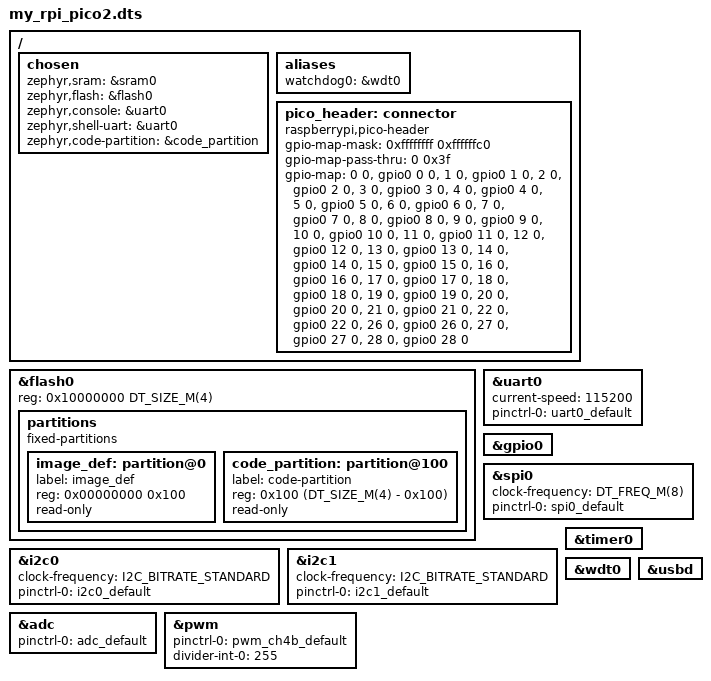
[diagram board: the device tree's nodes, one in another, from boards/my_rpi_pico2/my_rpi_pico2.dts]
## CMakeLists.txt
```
cmake_minimum_required(VERSION 3.20.0)

list(APPEND BOARD_ROOT ${CMAKE_CURRENT_SOURCE_DIR})
find_package(Zephyr REQUIRED HINTS $ENV{ZEPHYR_BASE})
project(my_zephyr_app)

target_sources(app PRIVATE src/main.cpp)
zephyr_syscall_include_directories(drivers/my_pico2driver/include)
add_subdirectory(drivers/my_pico2driver)
```

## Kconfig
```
menuconfig LED_SUBSYSTEM
    bool "LED Subsytem"
    default y

if LED_SUBSYSTEM

choice
    prompt "LED blink sleep time"
    default BLINK_SPEED_1000MS

config BLINK_SPEED_250MS
    bool "250ms (quick)"

config BLINK_SPEED_500MS
    bool "500ms (fast)"

config BLINK_SPEED_1000MS
    bool "1s (medium)"

config BLINK_SPEED_2000MS
    bool "2s (slow)"

endchoice

config BLINK_SLEEP_TIME_MS
    int # no prompt
    default 250 if BLINK_SPEED_250MS 
    default 500 if BLINK_SPEED_500MS 
    default 1000 if BLINK_SPEED_1000MS 
    default 2000 if BLINK_SPEED_2000MS 
    default 0

menuconfig ADV_LED_SETTINGS
    bool "Advanced LED settings"
    
if ADV_LED_SETTINGS

config LED_BRIGHTNESS
    int "LED brightness (0-100)"
    range 0 100
    default 100

config LED_FADE_DURATION_MS
    int "LED fade duration (ms)"
    range 0 5000
    default 500
  
endif # ADV_LED_SETTINGS

menu "Expert settings"
    visible if ADV_LED_SETTINGS

config ENABLE_LED_DEBUGGING
    bool "Enable LED debugging"

config CUSTOM_BLINK_PATTERN
    bool "Custom blink pattern"

endmenu

config APP_HEARTBEAT_PERIOD_MS
    int "App led blink period" 
    range 100 2000
    default 500

endif # LED_SUBSYSTEM

source "Kconfig.zephyr"
rsource "drivers/my_pico2driver/Kconfig"
```

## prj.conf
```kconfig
CONFIG_GPIO=y
CONFIG_LOG=y
CONFIG_MY_PICO2DRIVER=y
CONFIG_APPLICATION_DEFINED_SYSCALL=y

CONFIG_SERIAL=y
CONFIG_CONSOLE=y
CONFIG_UART_CONSOLE=y
CONFIG_STDOUT_CONSOLE=y
CONFIG_UART_LINE_CTRL=y

CONFIG_USB_DEVICE_STACK_NEXT=y
CONFIG_USB_CDC_ACM=y
CONFIG_CDC_ACM_SERIAL_INITIALIZE_AT_BOOT=y
CONFIG_CDC_ACM_SERIAL_PID=0x0004
CONFIG_CDC_ACM_SERIAL_PRODUCT_STRING="pico2 USBD console"

CONFIG_SHELL=y
CONFIG_MY_PICO2DRIVER_SHELL=y
```

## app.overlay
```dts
/ {
    aliases {
        app-led = &led0;
    };

    chosen {
        zephyr,console = &cdc_acm_uart0;
        zephyr,shell-uart = &cdc_acm_uart0;
    };

    my_pico2driver0: my_pico2driver {
        compatible = "my,pico2driver";
        status = "okay";
    };
};

&zephyr_udc0 {
    cdc_acm_uart0: cdc_acm_uart0 {
        compatible = "zephyr,cdc-acm-uart";
    };
};
```

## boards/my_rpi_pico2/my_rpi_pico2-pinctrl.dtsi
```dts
/*
 * Copyright (c) 2024, Andrew Featherstone
 * SPDX-License-Identifier: Apache-2.0
 */

#include <zephyr/dt-bindings/pinctrl/rpi-pico-rp2350a-pinctrl.h>

#include "my_rpi_pico-pinctrl-common.dtsi"
```

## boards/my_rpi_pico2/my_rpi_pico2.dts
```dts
/*
 * Copyright (c) 2024 Andrew Featherstone
 *
 * SPDX-License-Identifier: Apache-2.0
 */

#include <freq.h>

#include <zephyr/dt-bindings/i2c/i2c.h>
#include <zephyr/dt-bindings/pwm/pwm.h>

#include "my_rpi_pico2-pinctrl.dtsi"
#include "my_rpi_pico-led.dtsi"

/ {
	chosen {
		zephyr,sram = &sram0;
		zephyr,flash = &flash0;
		zephyr,console = &uart0;
		zephyr,shell-uart = &uart0;
		zephyr,code-partition = &code_partition;
	};

	aliases {
		watchdog0 = &wdt0;
	};

	pico_header: connector {
		compatible = "raspberrypi,pico-header";
		#gpio-cells = <2>;
		gpio-map-mask = <0xffffffff 0xffffffc0>;
		gpio-map-pass-thru = <0 0x3f>;
		gpio-map = <0 0 &gpio0 0 0>,	/* GP0 */
			<1 0 &gpio0 1 0>,	/* GP1 */
			<2 0 &gpio0 2 0>,	/* GP2 */
			<3 0 &gpio0 3 0>,	/* GP3 */
			<4 0 &gpio0 4 0>,	/* GP4 */
			<5 0 &gpio0 5 0>,	/* GP5 */
			<6 0 &gpio0 6 0>,	/* GP6 */
			<7 0 &gpio0 7 0>,	/* GP7 */
			<8 0 &gpio0 8 0>,	/* GP8 */
			<9 0 &gpio0 9 0>,	/* GP9 */
			<10 0 &gpio0 10 0>,	/* GP10 */
			<11 0 &gpio0 11 0>,	/* GP11 */
			<12 0 &gpio0 12 0>,	/* GP12 */
			<13 0 &gpio0 13 0>,	/* GP13 */
			<14 0 &gpio0 14 0>,	/* GP14 */
			<15 0 &gpio0 15 0>,	/* GP15 */
			<16 0 &gpio0 16 0>,	/* GP16 */
			<17 0 &gpio0 17 0>,	/* GP17 */
			<18 0 &gpio0 18 0>,	/* GP18 */
			<19 0 &gpio0 19 0>,	/* GP19 */
			<20 0 &gpio0 20 0>,	/* GP20 */
			<21 0 &gpio0 21 0>,	/* GP21 */
			<22 0 &gpio0 22 0>,	/* GP22 */
			<26 0 &gpio0 26 0>,	/* GP26 */
			<27 0 &gpio0 27 0>,	/* GP27 */
			<28 0 &gpio0 28 0>;	/* GP28 */
	};
};

&flash0 {
	reg = <0x10000000 DT_SIZE_M(4)>;

	partitions {
		compatible = "fixed-partitions";
		#address-cells = <1>;
		#size-cells = <1>;

		/* Reserved memory for an image definition block. The block is much
		 * smaller than 256 bytes, but in practice the linker places the vector
		 * table at a much larger alignment offset.
		 */
		image_def: partition@0 {
			label = "image_def";
			reg = <0x00000000 0x100>;
			read-only;
		};

		/*
		 * Usable flash. Starts at 0x100, after the image definition block.
		 * The partition size is 4MB minus the 0x100 bytes taken by the
		 * image definition.
		 */
		code_partition: partition@100 {
			label = "code-partition";
			reg = <0x100 (DT_SIZE_M(4) - 0x100)>;
			read-only;
		};
	};
};

&uart0 {
	current-speed = <115200>;
	status = "okay";
	pinctrl-0 = <&uart0_default>;
	pinctrl-names = "default";
};

gpio0_lo: &gpio0 {
	status = "okay";
};

&spi0 {
	clock-frequency = <DT_FREQ_M(8)>;
	pinctrl-0 = <&spi0_default>;
	pinctrl-names = "default";
};

&i2c0 {
	clock-frequency = <I2C_BITRATE_STANDARD>;
	pinctrl-0 = <&i2c0_default>;
	pinctrl-names = "default";
	status = "okay";
};

&i2c1 {
	clock-frequency = <I2C_BITRATE_STANDARD>;
	pinctrl-0 = <&i2c1_default>;
	pinctrl-names = "default";
	status = "okay";
};

&adc {
	pinctrl-0 = <&adc_default>;
	pinctrl-names = "default";
	status = "okay";
};

&pwm {
	pinctrl-0 = <&pwm_ch4b_default>;
	pinctrl-names = "default";
	divider-int-0 = <255>;
};

&timer0 {
	status = "okay";
};

&wdt0 {
	status = "okay";
};

zephyr_udc0: &usbd {
	status = "okay";
};

pico_serial: &uart0 {};
```

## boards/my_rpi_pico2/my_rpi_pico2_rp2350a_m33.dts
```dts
/*
 * Copyright (c) 2024 Andrew Featherstone
 *
 * SPDX-License-Identifier: Apache-2.0
 */

/dts-v1/;

/* The build system assumes that there's a cpucluster-specific file.
 *
 * This file provides composition of the device tree:
 * 1. The common features of the SoC
 * 2. Core-specific configuration.
 * 3. Board-specific configuration.
 */
#include <raspberrypi/rpi_pico/rp2350a.dtsi>
#include <raspberrypi/rpi_pico/m33.dtsi>

/* there's nothing specific to the Cortex-M33 cores vs the (not yet
 * implemented) Hazard3 cores.
 */
#include "my_rpi_pico2.dtsi"
```

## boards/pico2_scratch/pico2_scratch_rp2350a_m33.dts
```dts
/dts-v1/;

/* The build system assumes that there's a cpucluster-specific file.
 *
 * This file provides composition of the device tree:
 * 1. The common features of the SoC
 * 2. Core-specific configuration.
 * 3. Board-specific configuration.
 */
#include <raspberrypi/rpi_pico/rp2350a.dtsi>
#include <raspberrypi/rpi_pico/m33.dtsi>

#include <zephyr/dt-bindings/pinctrl/rpi-pico-rp2350a-pinctrl.h>

/ {
    model = "Pico2 from Sratch";
    compatible = "myrasberrypi,pico2_scratch";

	chosen {
		zephyr,sram = &sram0;
		zephyr,flash = &flash0;
		zephyr,console = &uart0;
		zephyr,shell-uart = &uart0;
		zephyr,code-partition = &code_partition;
	};

    leds {
        compatible = "gpio-leds";
        led0: led_0 {
            gpios = <&gpio0 25 GPIO_ACTIVE_HIGH>;
            label = "LED";
        };
    };

    aliases {
		led0 = &led0;
    };
};

&pinctrl {
    uart0_default: uart0_default {
        group1 {
            pinmux = <UART0_TX_P0>;
        };  
        group2 {
            pinmux = <UART0_RX_P1>;
            input-enable;
        };  
    }; 
};

&flash0 {
	reg = <0x10000000 DT_SIZE_M(4)>;

	partitions {
		compatible = "fixed-partitions";
		#address-cells = <1>;
		#size-cells = <1>;

		/* Reserved memory for an image definition block. The block is much
		 * smaller than 256 bytes, but in practice the linker places the vector
		 * table at a much larger alignment offset.
		 */
		image_def: partition@0 {
			label = "image_def";
			reg = <0x00000000 0x100>;
			read-only;
		};

		/*
		 * Usable flash. Starts at 0x100, after the image definition block.
		 * The partition size is 4MB minus the 0x100 bytes taken by the
		 * image definition.
		 */
		code_partition: partition@100 {
			label = "code-partition";
			reg = <0x100 (DT_SIZE_M(4) - 0x100)>;
			read-only;
		};
	};
};

&uart0 {
	current-speed = <115200>;
	status = "okay";
	pinctrl-0 = <&uart0_default>;
	pinctrl-names = "default";
};

gpio0_lo: &gpio0 {
	status = "okay";
};

pico_serial: &uart0 {};
```

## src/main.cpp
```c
#include <zephyr/drivers/gpio.h>
#include <zephyr/drivers/sensor.h>
#include <zephyr/drivers/uart.h>
#include <zephyr/usb/usb_device.h>

#include <zephyr/kernel.h>
#include <zephyr/logging/log.h>
#include <zephyr/sys/printk.h>

#include <mypico2.h>

#define LED_DEFAULT_BLINK_TIME 3000

/* Use the USB CDC ACM - Lack for serial cable */
BUILD_ASSERT(DT_NODE_HAS_COMPAT(DT_CHOSEN(zephyr_console), zephyr_cdc_acm_uart), "Console device is not ACM CDC UART device");

LOG_MODULE_REGISTER(main, LOG_LEVEL_INF);

int main(void)
{
    bool led_state = false;
    struct sensor_value sval;
    const struct device* sensor_dev = DEVICE_DT_GET(DT_NODELABEL(my_pico2driver0));
    int ret = -1;

    const struct device *usb_dev = DEVICE_DT_GET(DT_CHOSEN(zephyr_console));
    uint32_t dtr = 0;

    /* Poll if the DTR flag was set */
    while (!dtr) {
        uart_line_ctrl_get(usb_dev, UART_LINE_CTRL_DTR, &dtr);
        /* Give CPU resources to low priority threads. */
        k_sleep(K_MSEC(100));
    }

/* Use the Blink app only when shell is not enabled*/
#ifndef CONFIG_MY_PICO2DRIVER_SHELL
#ifndef CONFIG_APP_HEARTBEAT_PERIOD_MS
        LOG_INF("Using defaut blink time: %u ms", LED_DEFAULT_BLINK_TIME);
#endif
    while (1) {

        if (led_state) {
            // Turn off the LED
            ret = sensor_channel_get(sensor_dev, SENSOR_CHAN_AMBIENT_TEMP, &sval);
        } else {
            // Turn on the LED
            ret = sensor_sample_fetch(sensor_dev);
        }
        led_state = !led_state;
        /*Custom API to set led state*/
        mypico2_set_led_state(sensor_dev, led_state);
#if CONFIG_APP_HEARTBEAT_PERIOD_MS
        k_msleep(CONFIG_APP_HEARTBEAT_PERIOD_MS);
#else
        k_msleep(LED_DEFAULT_BLINK_TIME);
#endif

    }
#else /* CONFIG_MY_PICO2DRIVER_SHELL */
    LOG_INF("blink App is disabled - sensor driver availble in shell commands");
#endif /* CONFIG_MY_PICO2DRIVER_SHELL */
    return 0;
}
```
